AUTOSAR XML (schema 00048)
package /ComponentTypes
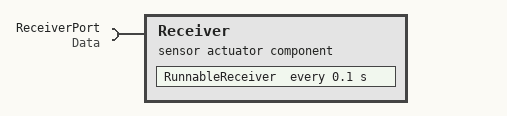
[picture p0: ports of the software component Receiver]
  sensor actuator sw component type Receiver
    require port ReceiverPort: queued-receiver-com-spec{data-element=Data1, queue-length=2}, required-interface=Data
    behavior ReceiverInternalBehavior
      timing event ReceiverTimingEvent: start-on-event=RunnableReceiver, period=0.1
      runnable RunnableReceiver
        data-receive-point-by-values:
          access ReceiveData: accessed-variable=ReceiverPort.Data1
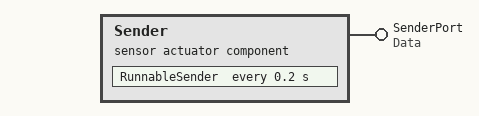
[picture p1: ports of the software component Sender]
  sensor actuator sw component type Sender
    provide port SenderPort: queued-sender-com-spec=Data1, provided-interface=Data
    behavior SenderInternalBehavior
      timing event SenderTimingEvent: start-on-event=RunnableSender, period=0.2
      runnable RunnableSender
        data-send-points:
          access SendData: accessed-variable=SenderPort.Data1
  composition sw component type SenderReceiver: assembly-sw-connector{provider=Sender.SenderPort, requester=Receiver.ReceiverPort}
    component Receiver: type=Receiver
    component Sender: type=Sender
package /PortInterfaces
  sender receiver interface Data
    data Data1
